# NUC1xx_registers register map
File version: 0.1
CPU: 
Registers are 32-bit, read-write, reset 0x0 unless marked. A register's access mark holds for its fields unless they carry their own. Offsets are from the block's base; [hi:lo] are bit positions; lines under a group give offsets from that group; {n}, {i} and the like mark numbered series.

## PDMA_GCR — Registers group
Base 0x50008F00
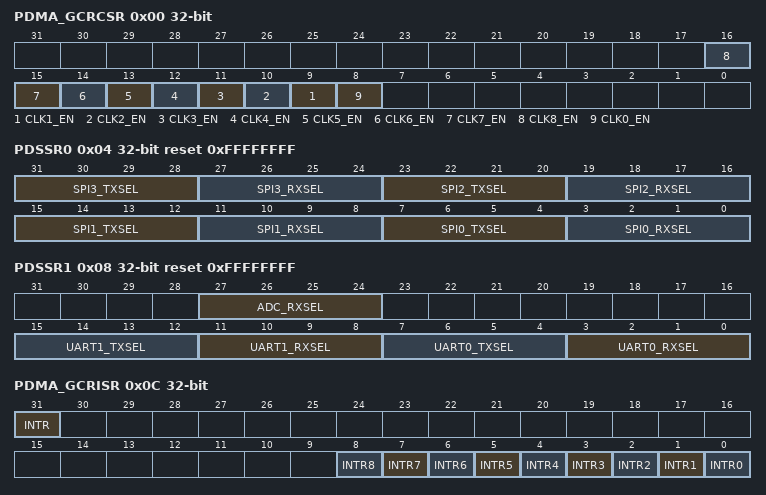
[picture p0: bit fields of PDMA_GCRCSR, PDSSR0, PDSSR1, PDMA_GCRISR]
0x00 PDMA_GCRCSR — PDMA Global Control Register
  [n+8] CLK{n}_EN (n=1..8) — PDMA Controller Channel {n} Clock Enable Control(Medium Density Only) 0 = Disable 1 = Enable
  [8] CLK0_EN — PDMA Controller Channel 0 Clock Enable Control 0 = Disable 1 = Enable
0x04 PDSSR0 reset 0xFFFFFFFF — PDMA Service Selection Control Register 0
  [31:28] SPI3_TXSEL — PDMA SPI3 TX Selection (Medium Density Only) This filed defines which PDMA channel is connected to the on-chip peripheral SPI3 TX. Software can configure the TX channel setting by SPI3_TXSEL. The channel configuration is the same as SPI0_RXSEL field. Please refer to the explanation of SPI0_RXSEL.
  [27:24] SPI3_RXSEL — PDMA SPI3 RX Selection (Medium Density Only) This filed defines which PDMA channel is connected to the on-chip peripheral SPI3 RX. Software can configure the RX channel setting by SPI3_RXSEL. The channel configuration is the same as SPI0_RXSEL field. Please refer to the explanation of SPI0_RXSEL.
  [23:20] SPI2_TXSEL — PDMA SPI2 TX Selection (Medium Density Only) This filed defines which PDMA channel is connected to the on-chip peripheral SPI2 TX. Software can configure the TX channel setting by SPI2_TXSEL. The channel configuration is the same as SPI0_RXSEL field. Please refer to the explanation of SPI0_RXSEL.
  [19:16] SPI2_RXSEL — PDMA SPI2 RX Selection (Medium Density Only) This filed defines which PDMA channel is connected to the on-chip peripheral SPI2 RX. Software can configure the RX channel setting by SPI2_RXSEL. The channel configuration is the same as SPI0_RXSEL field. Please refer to the explanation of SPI0_RXSEL.
  [15:12] SPI1_TXSEL — PDMA SPI1 TX Selection This filed defines which PDMA channel is connected to the on-chip peripheral SPI1 TX. Software can configure the TX channel setting by SPI1_TXSEL. The channel configuration is the same as SPI0_RXSEL field. Please refer to the explanation of SPI0_RXSEL.
  [11:8] SPI1_RXSEL — PDMA SPI1 RX Selection This filed defines which PDMA channel is connected to the on-chip peripheral SPI1 RX. Software can configure the RX channel setting by SPI1_RXSEL. The channel configuration is the same as SPI0_RXSEL field. Please refer to the explanation of SPI0_RXSEL.
  [7:4] SPI0_TXSEL — PDMA SPI0 TX Selection This filed defines which PDMA channel is connected to the on-chip peripheral SPI0 TX. Software can configure the TX channel setting by SPI0_TXSEL. The channel configuration is the same as SPI0_RXSEL field. Please refer to the explanation of SPI0_RXSEL.
  [3:0] SPI0_RXSEL — PDMA SPI0 RX Selection This filed defines which PDMA channel is connected to the on-chip peripheral SPI0 RX. Software can change the channel RX setting by SPI0_RXSEL 4'b0000: CH0 4'b0001: CH1 4'b0010: CH2 4'b0011: CH3 4'b0100: CH4 4'b0101: CH5 4'b0110: CH6 4'b0111: CH7 4'b1000: CH8 Others : Reserved Note : Ex : SPI0_RXSEL = 4'b0110, that means SPI0_RX is connected to PDMA_CH6(Low Density should set as 4'b0000 for PDMA channel 0 only)
0x08 PDSSR1 reset 0xFFFFFFFF — PDMA Service Selection Control Register 1
  [27:24] ADC_RXSEL — PDMA ADC RX Selection This filed defines which PDMA channel is connected to the on-chip peripheral ADC RX. Software can configure the RX channel setting by ADC_RXSEL. The channel configuration is the same as UART0_RXSEL field. Please refer to the explanation of UART0_RXSEL
  [15:12] UART1_TXSEL — PDMA UART1 TX Selection This filed defines which PDMA channel is connected to the on-chip peripheral UART1 TX. Software can configure the TX channel setting by UART1_TXSEL. The channel configuration is the same as UART0_RXSEL field. Please refer to the explanation of UART0_RXSEL
  [11:8] UART1_RXSEL — PDMA UART1 RX Selection This filed defines which PDMA channel is connected to the on-chip peripheral UART1 RX. Software can configure the RX channel setting by UART1_RXSEL. The channel configuration is the same as UART0_RXSEL field. Please refer to the explanation of UART0_RXSEL
  [7:4] UART0_TXSEL — PDMA UART0 TX Selection This filed defines which PDMA channel is connected to the on-chip peripheral UART0 TX. Software can configure the TX channel setting by UART0_TXSEL. The channel configuration is the same as UART0_RXSEL field. Please refer to the explanation of UART0_RXSEL
  [3:0] UART0_RXSEL — This filed defines which PDMA channel is connected to the on-chip peripheral UART0 RX. Software can change the channel RX setting by UART0_RXSEL 4'b0000: CH0 4'b0001: CH1 4'b0010: CH2 4'b0011: CH3 4'b0100: CH4 4'b0101: CH5 4'b0110: CH6 4'b0111: CH7 4'b1000: CH8 Others : Reserved Note : Ex : UART0_RXSEL = 4'b0110, that means UART0_RX is connected to PDMA_CH6(Low Density should set as 4'b0000 for PDMA channel 0 only)
0x0C PDMA_GCRISR ro — PDMA Global Interrupt Register
  [31] INTR — Interrupt Pin Status This bit is the Interrupt pin status of PDMA controller. Note: This bit is read only
  [8] INTR8 — Interrupt Pin Status of Channel 4 (Medium Density Only) This bit is the Interrupt pin status of PDMA channel 8. Note: This bit is read only
  [7] INTR7 — Interrupt Pin Status of Channel 7 (Medium Density Only) This bit is the Interrupt pin status of PDMA channel 7. Note: This bit is read only
  [6] INTR6 — Interrupt Pin Status of Channel 6 (Medium Density Only) This bit is the Interrupt pin status of PDMA channel 6. Note: This bit is read only
  [n] INTR{n} (n=1..5) — Interrupt Pin Status of Channel {n} (Medium Density Only) This bit is the Interrupt pin status of PDMA channel{n}. Note: This bit is read only
  [0] INTR0 — Interrupt Pin Status of Channel 0 This bit is the Interrupt pin status of PDMA channel0. Note: This bit is read only
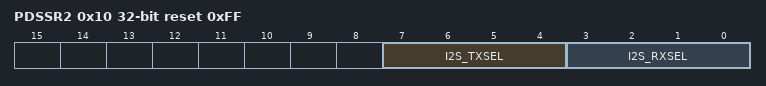
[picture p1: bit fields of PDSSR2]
0x10 PDSSR2 reset 0xFF — PDMA Service Selection Control Register 2
  [7:4] I2S_TXSEL — PDMA I2S TX Selection This filed defines which PDMA channel is connected to the on-chip peripheral I2S TX. Software can configure the TX channel setting by I2S_TXSEL. The channel configuration is the same as I2S_RXSEL field. Please refer to the explanation of I2S_RXSEL.
  [3:0] I2S_RXSEL — PDMA I2S RX Selection This filed defines which PDMA channel is connected to the on-chip peripheral I2S RX. Software can change the channel RX setting by I2S_RXSEL 4'b0000: CH0 4'b0001: CH1 4'b0010: CH2 4'b0011: CH3 4'b0100: CH4 4'b0101: CH5 4'b0110: CH6 4'b0111: CH7 4'b1000: CH8 Others : Reserved Note : Ex : I2S_RXSEL = 4'b0110, that means I2S_RX is connected to PDMA_CH6(Low Density should set as 4'b0000 for PDMA channel 0 only)
